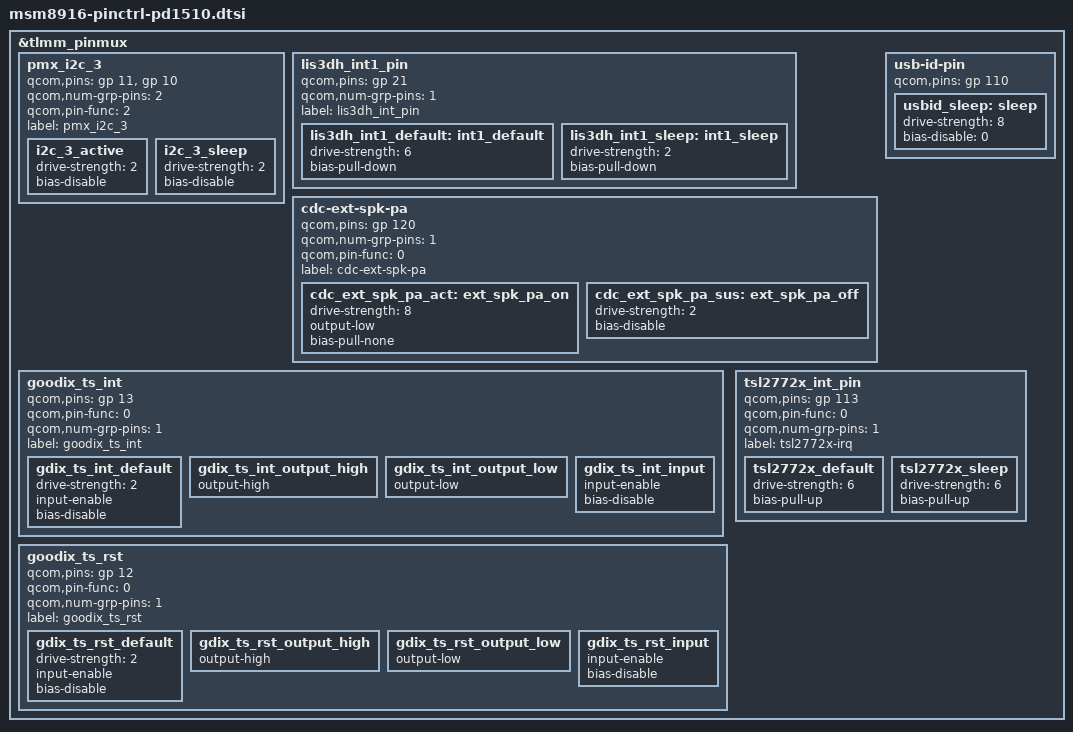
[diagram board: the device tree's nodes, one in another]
/* Copyright (c) 2018, The Linux Foundation. All rights reserved.
*  Copyright (c) 2018, Ketut P. Kumajaya.
*  Copyright (c) 2020, the_shahnawaz_sheikh (sheikhshahnawaz41299).
*
* This program is free software; you can redistribute it and/or modify
* it under the terms of the GNU General Public License version 2 and
* only version 2 as published by the Free Software Foundation.
*
* This program is distributed in the hope that it will be useful,
* but WITHOUT ANY WARRANTY; without even the implied warranty of
* MERCHANTABILITY or FITNESS FOR A PARTICULAR PURPOSE.  See the
* GNU General Public License for more details.
*/
 
&tlmm_pinmux {
	pmx_i2c_3 {
		/* CLK, DATA */
		qcom,pins = <&gp 11>, <&gp 10>;
		qcom,num-grp-pins = <2>;
		qcom,pin-func = <2>;
		label = "pmx_i2c_3";

		i2c_3_active: i2c_3_active {
			drive-strength = <2>; /* 2 MA */
			bias-disable;		  /* No PULL */
		};

		i2c_3_sleep: i2c_3_sleep {
			drive-strength = <2>; /* 2 MA */
			bias-disable;		  /* No PULL */
		};
	};

	lis3dh_int1_pin {
		qcom,pins = <&gp 21>;
		qcom,num-grp-pins = <1>;
		label = "lis3dh_int_pin";
		lis3dh_int1_default: int1_default {
			drive-strength = <6>;
			bias-pull-down;
		};
		lis3dh_int1_sleep: int1_sleep {
			drive-strength = <2>;
			bias-pull-down;
		};
	};

	cdc-ext-spk-pa {
		qcom,pins = <&gp 120>;
		qcom,num-grp-pins = <1>;
		qcom,pin-func = <0>;
		label = "cdc-ext-spk-pa";
		cdc_ext_spk_pa_act: ext_spk_pa_on {
			drive-strength = <8>;
			output-low;
			bias-pull-none;
		};
		cdc_ext_spk_pa_sus: ext_spk_pa_off {
			drive-strength = <2>;
			bias-disable;
		};
	};

	goodix_ts_int {
		qcom,pins = <&gp 13>;
		qcom,pin-func = <0>;
		qcom,num-grp-pins = <1>;
		label = "goodix_ts_int";

		gdix_ts_int_default: gdix_ts_int_default {
			drive-strength = <2>;
			input-enable;
			bias-disable;
		};

		gdix_ts_int_output_high: gdix_ts_int_output_high {
			output-high;
		};

		gdix_ts_int_output_low: gdix_ts_int_output_low {
			output-low;
		};

		gdix_ts_int_input: gdix_ts_int_input {
			input-enable;
			bias-disable;
		};
	};

	goodix_ts_rst {
		qcom,pins = <&gp 12>;
		qcom,pin-func = <0>;
		qcom,num-grp-pins = <1>;
		label = "goodix_ts_rst";

		gdix_ts_rst_default: gdix_ts_rst_default {
			drive-strength = <2>;
			input-enable;
			bias-disable;
		};

		gdix_ts_rst_output_high: gdix_ts_rst_output_high {
			output-high;
		};

		gdix_ts_rst_output_low: gdix_ts_rst_output_low {
			output-low;
		};

		gdix_ts_rst_input: gdix_ts_rst_input {
			input-enable;
			bias-disable;
		};
	};

	usb-id-pin {
		qcom,pins = <&gp 110>;

		usbid_sleep: sleep {
			drive-strength = <8>;
			bias-disable = <0>;
		};
	};
    
    tsl2772x_int_pin {
			qcom,pins = <&gp 113>;
			qcom,pin-func = <0>;
			qcom,num-grp-pins = <1>;
			label = "tsl2772x-irq";
			tsl2772x_default: tsl2772x_default {
				drive-strength = <6>;
				bias-pull-up;
			};
			tsl2772x_sleep: tsl2772x_sleep {
				drive-strength = <6>;
				bias-pull-up;
			};
		};
         
};
